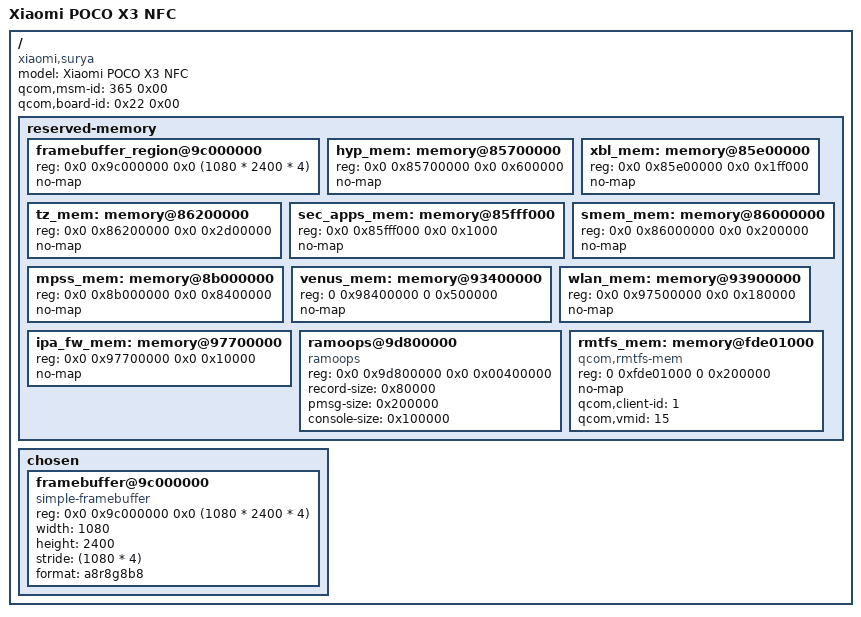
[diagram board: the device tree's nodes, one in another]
// SPDX-License-Identifier: GPL-2.0
/*
 * SM7150-AC Xiaomi POCO X3 NFC specific device tree
 *
 * Copyright (c) 2022, The Linux Foundation. All rights reserved.
 */

/dts-v1/;

#include <dt-bindings/gpio/gpio.h>
#include <dt-bindings/regulator/qcom,rpmh-regulator.h>
#include <dt-bindings/pinctrl/qcom,pmic-gpio.h>
#include "sm7150.dtsi"

/delete-node/ &rmtfs_mem;
/delete-node/ &ipa_fw_mem;
/delete-node/ &hyp_mem;
/delete-node/ &xbl_mem;
/delete-node/ &aop_mem;
/delete-node/ &aop_cmd_db_mem;
/delete-node/ &sec_apps_mem;
/delete-node/ &smem_mem;
/delete-node/ &tz_mem;

/ {
	model = "Xiaomi POCO X3 NFC";
	compatible = "xiaomi,surya", "qcom,sm7150";
	qcom,msm-id = <365 0x00>;
	qcom,board-id = <0x22 0x00>;

	reserved-memory {
		#address-cells = <2>;
		#size-cells = <2>;
		ranges;

		framebuffer_region@9c000000 {
			reg = <0x0 0x9c000000 0x0 (1080 * 2400 * 4)>;
			no-map;
		};

		hyp_mem: memory@85700000 {
			reg = <0x0 0x85700000 0x0 0x600000>;
			no-map;
		};

		xbl_mem: memory@85e00000 {
			reg = <0x0 0x85e00000 0x0 0x1ff000>;
			no-map;
		};

		tz_mem: memory@86200000 {
			reg = <0x0 0x86200000 0x0 0x2d00000>;
			no-map;
		};

		sec_apps_mem: memory@85fff000 {
			reg = <0x0 0x85fff000 0x0 0x1000>;
			no-map;
		};

		smem_mem: memory@86000000 {
			reg = <0x0 0x86000000 0x0 0x200000>;
			no-map;
		};

		mpss_mem: memory@8b000000 {
			reg = <0x0 0x8b000000 0x0 0x8400000>;
			no-map;
		};

		venus_mem: memory@93400000 {
			reg = <0 0x98400000 0 0x500000>;
			no-map;
		};

		wlan_mem: memory@93900000 {
			reg = <0x0 0x97500000 0x0 0x180000>;
			no-map;
		};

		ipa_fw_mem: memory@97700000 {
			reg = <0x0 0x97700000 0x0 0x10000>;
			no-map;
		};

		ramoops@9d800000 {
			compatible = "ramoops";
			reg = <0x0 0x9d800000 0x0 0x00400000>;

			record-size = <0x80000>;
			pmsg-size = <0x200000>;
			console-size = <0x100000>;
		};

		rmtfs_mem: memory@fde01000 {
			compatible = "qcom,rmtfs-mem";
			reg = <0 0xfde01000 0 0x200000>;
			no-map;

			qcom,client-id = <1>;
			qcom,vmid = <15>;
		};
	};

	chosen {
		#address-cells = <2>;
		#size-cells = <2>;
		ranges;
		framebuffer@9c000000 {
			compatible = "simple-framebuffer";
			reg = <0x0 0x9c000000 0x0 (1080 * 2400 * 4)>;
			width = <1080>;
			height = <2400>;
			stride = <(1080 * 4)>;
			format = "a8r8g8b8";
			/*
			 * That's a lot of clocks, but it's necessary due
			 * to unused clk cleanup & no panel driver yet..
			 */
			/*clocks = <&gcc GCC_DISP_HF_AXI_CLK>,
				 <&dispcc DISP_CC_MDSS_BYTE0_CLK>,
				 <&dispcc DISP_CC_MDSS_BYTE0_INTF_CLK>,
				 <&dispcc DISP_CC_MDSS_MDP_CLK>,
				 <&dispcc DISP_CC_MDSS_PCLK0_CLK>,
				 <&dispcc DISP_CC_MDSS_VSYNC_CLK>;
			power-domains = <&dispcc MDSS_GDSC>;*/
		};
	};
};
